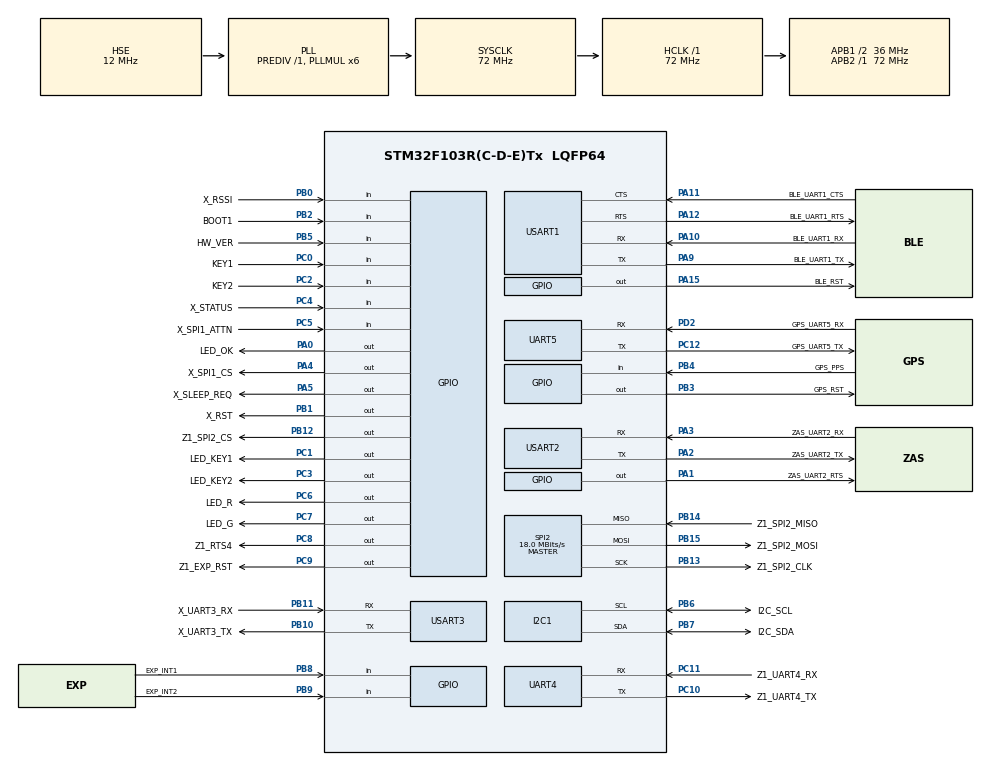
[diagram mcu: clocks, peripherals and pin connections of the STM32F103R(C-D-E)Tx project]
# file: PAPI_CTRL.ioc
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IWDG.Prescaler=IWDG_PRESCALER_16
Mcu.Family=STM32F1
Mcu.Name=STM32F103R(C-D-E)Tx
Mcu.Package=LQFP64
NVIC.PriorityGroup=NVIC_PRIORITYGROUP_4
PA0-WKUP.GPIO_Label=LED_OK
PA0-WKUP.Signal=GPIO_Output
PA1.GPIO_Label=ZAS_UART2_RTS
PA1.Signal=GPIO_Output
PA10.GPIO_Label=BLE_UART1_RX
PA10.Mode=Asynchronous
PA10.Signal=USART1_RX
PA11.GPIO_Label=BLE_UART1_CTS
PA11.Mode=CTS_RTS
PA11.Signal=USART1_CTS
PA12.GPIO_Label=BLE_UART1_RTS
PA12.Mode=CTS_RTS
PA12.Signal=USART1_RTS
PA13.Mode=Serial_Wire
PA13.Signal=SYS_JTMS-SWDIO
PA14.Mode=Serial_Wire
PA14.Signal=SYS_JTCK-SWCLK
PA15.GPIO_Label=BLE_RST
PA15.Signal=GPIO_Output
PA2.GPIO_Label=ZAS_UART2_TX
PA2.Mode=Asynchronous
PA2.Signal=USART2_TX
PA3.GPIO_Label=ZAS_UART2_RX
PA3.Mode=Asynchronous
PA3.Signal=USART2_RX
PA4.GPIO_Label=X_SPI1_CS
PA4.PinState=GPIO_PIN_SET
PA4.Signal=GPIO_Output
PA5.GPIO_Label=X_SLEEP_REQ
PA5.Signal=GPIO_Output
PA9.GPIO_Label=BLE_UART1_TX
PA9.Mode=Asynchronous
PA9.Signal=USART1_TX
PB0.GPIO_Label=X_RSSI
PB0.Signal=GPIO_Input
PB1.GPIO_Label=X_RST
PB1.Signal=GPIO_Output
PB10.GPIO_Label=X_UART3_TX
PB10.Mode=Asynchronous
PB10.Signal=USART3_TX
PB11.GPIO_Label=X_UART3_RX
PB11.Mode=Asynchronous
PB11.Signal=USART3_RX
PB12.GPIO_Label=Z1_SPI2_CS
PB12.Signal=GPIO_Output
PB13.GPIO_Label=Z1_SPI2_CLK
PB13.Mode=Full_Duplex_Master
PB13.Signal=SPI2_SCK
PB14.GPIO_Label=Z1_SPI2_MISO
PB14.Mode=Full_Duplex_Master
PB14.Signal=SPI2_MISO
PB15.GPIO_Label=Z1_SPI2_MOSI
PB15.Mode=Full_Duplex_Master
PB15.Signal=SPI2_MOSI
PB2.GPIO_Label=BOOT1
PB2.Signal=GPIO_Input
PB3.GPIO_Label=GPS_RST
PB3.Signal=GPIO_Output
PB4.GPIO_Label=GPS_PPS
PB4.Signal=GPIO_Input
PB5.GPIO_Label=HW_VER
PB5.Signal=GPIO_Input
PB6.GPIO_Label=I2C_SCL
PB6.Mode=I2C
PB6.Signal=I2C1_SCL
PB7.GPIO_Label=I2C_SDA
PB7.Mode=I2C
PB7.Signal=I2C1_SDA
PB8.GPIO_Label=EXP_INT1
PB8.GPIO_PuPd=GPIO_PULLUP
PB8.Signal=GPIO_Input
PB9.GPIO_Label=EXP_INT2
PB9.GPIO_PuPd=GPIO_PULLUP
PB9.Signal=GPIO_Input
PC0.GPIO_Label=KEY1
PC0.GPIO_PuPd=GPIO_PULLUP
PC0.Signal=GPIO_Input
PC1.GPIO_Label=LED_KEY1
PC1.Signal=GPIO_Output
PC10.GPIO_Label=Z1_UART4_TX
PC10.Mode=Asynchronous
PC10.Signal=UART4_TX
PC11.GPIO_Label=Z1_UART4_RX
PC11.Mode=Asynchronous
PC11.Signal=UART4_RX
PC12.GPIO_Label=GPS_UART5_TX
PC12.Mode=Asynchronous
PC12.Signal=UART5_TX
PC14-OSC32_IN.Mode=LSE-External-Oscillator
PC14-OSC32_IN.Signal=RCC_OSC32_IN
PC15-OSC32_OUT.Mode=LSE-External-Oscillator
PC15-OSC32_OUT.Signal=RCC_OSC32_OUT
PC2.GPIO_Label=KEY2
PC2.GPIO_PuPd=GPIO_PULLUP
PC2.Signal=GPIO_Input
PC3.GPIO_Label=LED_KEY2
PC3.Signal=GPIO_Output
PC4.GPIO_Label=X_STATUS
PC4.Signal=GPIO_Input
PC5.GPIO_Label=X_SPI1_ATTN
PC5.Signal=GPIO_Input
PC6.GPIO_Label=LED_R
PC6.Signal=GPIO_Output
PC7.GPIO_Label=LED_G
PC7.Signal=GPIO_Output
PC8.GPIO_Label=Z1_RTS4
PC8.Signal=GPIO_Output
PC9.GPIO_Label=Z1_EXP_RST
PC9.Signal=GPIO_Output
PD0-OSC_IN.Mode=HSE-External-Oscillator
PD0-OSC_IN.Signal=RCC_OSC_IN
PD1-OSC_OUT.Mode=HSE-External-Oscillator
PD1-OSC_OUT.Signal=RCC_OSC_OUT
PD2.GPIO_Label=GPS_UART5_RX
PD2.Mode=Asynchronous
PD2.Signal=UART5_RX
ProjectManager.HeapSize=0x200
ProjectManager.StackSize=0x400
ProjectManager.TargetToolchain=STM32CubeIDE
RCC.AHBFreq_Value=72000000
RCC.APB1CLKDivider=RCC_HCLK_DIV2
RCC.APB1Freq_Value=36000000
RCC.APB1TimFreq_Value=72000000
RCC.APB2Freq_Value=72000000
RCC.APB2TimFreq_Value=72000000
RCC.HCLKFreq_Value=72000000
RCC.HSE_VALUE=12000000
RCC.PLLMUL=RCC_PLL_MUL6
RCC.PLLSourceVirtual=RCC_PLLSOURCE_HSE
RCC.SYSCLKFreq_VALUE=72000000
RCC.SYSCLKSource=RCC_SYSCLKSOURCE_PLLCLK
RCC.USBFreq_Value=72000000
SPI2.BaudRatePrescaler=SPI_BAUDRATEPRESCALER_2
SPI2.CalculateBaudRate=18.0 MBits/s
SPI2.Direction=SPI_DIRECTION_2LINES
SPI2.Mode=SPI_MODE_MASTER
SPI2.VirtualType=VM_MASTER
UART4.VirtualMode=Asynchronous
UART5.VirtualMode=Asynchronous
USART1.VirtualMode=VM_ASYNC
USART2.VirtualMode=VM_ASYNC
USART3.VirtualMode=VM_ASYNC
VP_IWDG_VS_IWDG.Mode=IWDG_Activate
board=custom

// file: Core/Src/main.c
/* USER CODE BEGIN Header */
/**
  ******************************************************************************
  * @file           : main.c
  * @brief          : Main program body
  ******************************************************************************
  * @attention
  *
  * <h2><center>&copy; Copyright (c) 2022 STMicroelectronics.
  * All rights reserved.</center></h2>
  *
  * This software component is licensed by ST under BSD 3-Clause license,
  * the "License"; You may not use this file except in compliance with the
  * License. You may obtain a copy of the License at:
  *                        opensource.org/licenses/BSD-3-Clause
  *
  ******************************************************************************
  */
/* USER CODE END Header */
#include "main.h"

I2C_HandleTypeDef hi2c1;

IWDG_HandleTypeDef hiwdg;

SPI_HandleTypeDef hspi2;

UART_HandleTypeDef huart4;
UART_HandleTypeDef huart5;
UART_HandleTypeDef huart1;
UART_HandleTypeDef huart2;
UART_HandleTypeDef huart3;

void SystemClock_Config(void);
static void MX_GPIO_Init(void);
static void MX_I2C1_Init(void);
static void MX_SPI2_Init(void);
static void MX_UART4_Init(void);
static void MX_UART5_Init(void);
static void MX_USART1_UART_Init(void);
static void MX_USART2_UART_Init(void);
static void MX_USART3_UART_Init(void);
static void MX_IWDG_Init(void);

/* USER CODE BEGIN 0 */

extern void uMain(void);

void MxStart(void) {
	  MX_GPIO_Init();
	  MX_I2C1_Init();
//	  MX_SPI1_Init();
//	  MX_SPI2_Init();
//	  MX_UART4_Init();
//	  MX_UART5_Init();
//	  MX_USART1_UART_Init();
//	  MX_USART2_UART_Init();
//	  MX_USART3_UART_Init();
//	  MX_IWDG_Init();
}

/* USER CODE END 0 */

int main(void)
{

  /* MCU Configuration--------------------------------------------------------*/

  /* Reset of all peripherals, Initializes the Flash interface and the Systick. */
  HAL_Init();

  /* Configure the system clock */
  SystemClock_Config();

  /* USER CODE BEGIN SysInit */
	uMain();

  /* USER CODE END SysInit */

  /* Initialize all configured peripherals */
  MX_GPIO_Init();
  MX_I2C1_Init();
  MX_SPI2_Init();
  MX_UART4_Init();
  MX_UART5_Init();
  MX_USART1_UART_Init();
  MX_USART2_UART_Init();
  MX_USART3_UART_Init();
  MX_IWDG_Init();

  /* Infinite loop */
  while (1)
  {

  }
}

void SystemClock_Config(void)
{
  RCC_OscInitTypeDef RCC_OscInitStruct = {0};
  RCC_ClkInitTypeDef RCC_ClkInitStruct = {0};

  /** Initializes the RCC Oscillators according to the specified parameters
  * in the RCC_OscInitTypeDef structure.
  */
  RCC_OscInitStruct.OscillatorType = RCC_OSCILLATORTYPE_LSI|RCC_OSCILLATORTYPE_HSE;
  RCC_OscInitStruct.HSEState = RCC_HSE_ON;
  RCC_OscInitStruct.HSEPredivValue = RCC_HSE_PREDIV_DIV1;
  RCC_OscInitStruct.HSIState = RCC_HSI_ON;
  RCC_OscInitStruct.LSIState = RCC_LSI_ON;
  RCC_OscInitStruct.PLL.PLLState = RCC_PLL_ON;
  RCC_OscInitStruct.PLL.PLLSource = RCC_PLLSOURCE_HSE;
  RCC_OscInitStruct.PLL.PLLMUL = RCC_PLL_MUL6;
  if (HAL_RCC_OscConfig(&RCC_OscInitStruct) != HAL_OK)
  {
    Error_Handler();
  }
  /** Initializes the CPU, AHB and APB buses clocks
  */
  RCC_ClkInitStruct.ClockType = RCC_CLOCKTYPE_HCLK|RCC_CLOCKTYPE_SYSCLK
                              |RCC_CLOCKTYPE_PCLK1|RCC_CLOCKTYPE_PCLK2;
  RCC_ClkInitStruct.SYSCLKSource = RCC_SYSCLKSOURCE_PLLCLK;
  RCC_ClkInitStruct.AHBCLKDivider = RCC_SYSCLK_DIV1;
  RCC_ClkInitStruct.APB1CLKDivider = RCC_HCLK_DIV2;
  RCC_ClkInitStruct.APB2CLKDivider = RCC_HCLK_DIV1;

  if (HAL_RCC_ClockConfig(&RCC_ClkInitStruct, FLASH_LATENCY_2) != HAL_OK)
  {
    Error_Handler();
  }
}

static void MX_I2C1_Init(void)
{

  hi2c1.Instance = I2C1;
  hi2c1.Init.ClockSpeed = 100000;
  hi2c1.Init.DutyCycle = I2C_DUTYCYCLE_2;
  hi2c1.Init.OwnAddress1 = 0;
  hi2c1.Init.AddressingMode = I2C_ADDRESSINGMODE_7BIT;
  hi2c1.Init.DualAddressMode = I2C_DUALADDRESS_DISABLE;
  hi2c1.Init.OwnAddress2 = 0;
  hi2c1.Init.GeneralCallMode = I2C_GENERALCALL_DISABLE;
  hi2c1.Init.NoStretchMode = I2C_NOSTRETCH_DISABLE;
  if (HAL_I2C_Init(&hi2c1) != HAL_OK)
  {
    Error_Handler();
  }

}

static void MX_IWDG_Init(void)
{

  hiwdg.Instance = IWDG;
  hiwdg.Init.Prescaler = IWDG_PRESCALER_16;
  hiwdg.Init.Reload = 4095;
  if (HAL_IWDG_Init(&hiwdg) != HAL_OK)
  {
    Error_Handler();
  }

}

static void MX_SPI2_Init(void)
{

  /* SPI2 parameter configuration*/
  hspi2.Instance = SPI2;
  hspi2.Init.Mode = SPI_MODE_MASTER;
  hspi2.Init.Direction = SPI_DIRECTION_2LINES;
  hspi2.Init.DataSize = SPI_DATASIZE_8BIT;
  hspi2.Init.CLKPolarity = SPI_POLARITY_LOW;
  hspi2.Init.CLKPhase = SPI_PHASE_1EDGE;
  hspi2.Init.NSS = SPI_NSS_SOFT;
  hspi2.Init.BaudRatePrescaler = SPI_BAUDRATEPRESCALER_2;
  hspi2.Init.FirstBit = SPI_FIRSTBIT_MSB;
  hspi2.Init.TIMode = SPI_TIMODE_DISABLE;
  hspi2.Init.CRCCalculation = SPI_CRCCALCULATION_DISABLE;
  hspi2.Init.CRCPolynomial = 10;
  if (HAL_SPI_Init(&hspi2) != HAL_OK)
  {
    Error_Handler();
  }

}

static void MX_UART4_Init(void)
{

  huart4.Instance = UART4;
  huart4.Init.BaudRate = 115200;
  huart4.Init.WordLength = UART_WORDLENGTH_8B;
  huart4.Init.StopBits = UART_STOPBITS_1;
  huart4.Init.Parity = UART_PARITY_NONE;
  huart4.Init.Mode = UART_MODE_TX_RX;
  huart4.Init.HwFlowCtl = UART_HWCONTROL_NONE;
  huart4.Init.OverSampling = UART_OVERSAMPLING_16;
  if (HAL_UART_Init(&huart4) != HAL_OK)
  {
    Error_Handler();
  }

}

static void MX_UART5_Init(void)
{

  huart5.Instance = UART5;
  huart5.Init.BaudRate = 115200;
  huart5.Init.WordLength = UART_WORDLENGTH_8B;
  huart5.Init.StopBits = UART_STOPBITS_1;
  huart5.Init.Parity = UART_PARITY_NONE;
  huart5.Init.Mode = UART_MODE_TX_RX;
  huart5.Init.HwFlowCtl = UART_HWCONTROL_NONE;
  huart5.Init.OverSampling = UART_OVERSAMPLING_16;
  if (HAL_UART_Init(&huart5) != HAL_OK)
  {
    Error_Handler();
  }

}

static void MX_USART1_UART_Init(void)
{

  huart1.Instance = USART1;
  huart1.Init.BaudRate = 115200;
  huart1.Init.WordLength = UART_WORDLENGTH_8B;
  huart1.Init.StopBits = UART_STOPBITS_1;
  huart1.Init.Parity = UART_PARITY_NONE;
  huart1.Init.Mode = UART_MODE_TX_RX;
  huart1.Init.HwFlowCtl = UART_HWCONTROL_RTS_CTS;
  huart1.Init.OverSampling = UART_OVERSAMPLING_16;
  if (HAL_UART_Init(&huart1) != HAL_OK)
  {
    Error_Handler();
  }

}

static void MX_USART2_UART_Init(void)
{

  huart2.Instance = USART2;
  huart2.Init.BaudRate = 115200;
  huart2.Init.WordLength = UART_WORDLENGTH_8B;
  huart2.Init.StopBits = UART_STOPBITS_1;
  huart2.Init.Parity = UART_PARITY_NONE;
  huart2.Init.Mode = UART_MODE_TX_RX;
  huart2.Init.HwFlowCtl = UART_HWCONTROL_NONE;
  huart2.Init.OverSampling = UART_OVERSAMPLING_16;
  if (HAL_UART_Init(&huart2) != HAL_OK)
  {
    Error_Handler();
  }

}

static void MX_USART3_UART_Init(void)
{

  huart3.Instance = USART3;
  huart3.Init.BaudRate = 115200;
  huart3.Init.WordLength = UART_WORDLENGTH_8B;
  huart3.Init.StopBits = UART_STOPBITS_1;
  huart3.Init.Parity = UART_PARITY_NONE;
  huart3.Init.Mode = UART_MODE_TX_RX;
  huart3.Init.HwFlowCtl = UART_HWCONTROL_NONE;
  huart3.Init.OverSampling = UART_OVERSAMPLING_16;
  if (HAL_UART_Init(&huart3) != HAL_OK)
  {
    Error_Handler();
  }

}

static void MX_GPIO_Init(void)
{
  GPIO_InitTypeDef GPIO_InitStruct = {0};

  /* GPIO Ports Clock Enable */
  __HAL_RCC_GPIOC_CLK_ENABLE();
  __HAL_RCC_GPIOD_CLK_ENABLE();
  __HAL_RCC_GPIOA_CLK_ENABLE();
  __HAL_RCC_GPIOB_CLK_ENABLE();

  /*Configure GPIO pin Output Level */
  HAL_GPIO_WritePin(GPIOC, LED_KEY1_Pin|LED_KEY2_Pin|LED_R_Pin|LED_G_Pin
                          |Z1_RTS4_Pin|Z1_EXP_RST_Pin, GPIO_PIN_RESET);

  /*Configure GPIO pin Output Level */
  HAL_GPIO_WritePin(GPIOA, LED_OK_Pin|ZAS_UART2_RTS_Pin|X_SLEEP_REQ_Pin|BLE_RST_Pin, GPIO_PIN_RESET);

  /*Configure GPIO pin Output Level */
  HAL_GPIO_WritePin(X_SPI1_CS_GPIO_Port, X_SPI1_CS_Pin, GPIO_PIN_SET);

  /*Configure GPIO pin Output Level */
  HAL_GPIO_WritePin(GPIOB, X_RST_Pin|Z1_SPI2_CS_Pin|GPS_RST_Pin, GPIO_PIN_RESET);

  /*Configure GPIO pins : KEY1_Pin KEY2_Pin */
  GPIO_InitStruct.Pin = KEY1_Pin|KEY2_Pin;
  GPIO_InitStruct.Mode = GPIO_MODE_INPUT;
  GPIO_InitStruct.Pull = GPIO_PULLUP;
  HAL_GPIO_Init(GPIOC, &GPIO_InitStruct);

  /*Configure GPIO pins : LED_KEY1_Pin LED_KEY2_Pin LED_R_Pin LED_G_Pin
                           Z1_RTS4_Pin Z1_EXP_RST_Pin */
  GPIO_InitStruct.Pin = LED_KEY1_Pin|LED_KEY2_Pin|LED_R_Pin|LED_G_Pin
                          |Z1_RTS4_Pin|Z1_EXP_RST_Pin;
  GPIO_InitStruct.Mode = GPIO_MODE_OUTPUT_PP;
  GPIO_InitStruct.Pull = GPIO_NOPULL;
  GPIO_InitStruct.Speed = GPIO_SPEED_FREQ_LOW;
  HAL_GPIO_Init(GPIOC, &GPIO_InitStruct);

  /*Configure GPIO pins : LED_OK_Pin ZAS_UART2_RTS_Pin X_SPI1_CS_Pin X_SLEEP_REQ_Pin
                           BLE_RST_Pin */
  GPIO_InitStruct.Pin = LED_OK_Pin|ZAS_UART2_RTS_Pin|X_SPI1_CS_Pin|X_SLEEP_REQ_Pin
                          |BLE_RST_Pin;
  GPIO_InitStruct.Mode = GPIO_MODE_OUTPUT_PP;
  GPIO_InitStruct.Pull = GPIO_NOPULL;
  GPIO_InitStruct.Speed = GPIO_SPEED_FREQ_LOW;
  HAL_GPIO_Init(GPIOA, &GPIO_InitStruct);

  /*Configure GPIO pins : X_STATUS_Pin X_SPI1_ATTN_Pin */
  GPIO_InitStruct.Pin = X_STATUS_Pin|X_SPI1_ATTN_Pin;
  GPIO_InitStruct.Mode = GPIO_MODE_INPUT;
  GPIO_InitStruct.Pull = GPIO_NOPULL;
  HAL_GPIO_Init(GPIOC, &GPIO_InitStruct);

  /*Configure GPIO pins : X_RSSI_Pin BOOT1_Pin GPS_PPS_Pin HW_VER_Pin */
  GPIO_InitStruct.Pin = X_RSSI_Pin|BOOT1_Pin|GPS_PPS_Pin|HW_VER_Pin;
  GPIO_InitStruct.Mode = GPIO_MODE_INPUT;
  GPIO_InitStruct.Pull = GPIO_NOPULL;
  HAL_GPIO_Init(GPIOB, &GPIO_InitStruct);

  /*Configure GPIO pins : X_RST_Pin Z1_SPI2_CS_Pin GPS_RST_Pin */
  GPIO_InitStruct.Pin = X_RST_Pin|Z1_SPI2_CS_Pin|GPS_RST_Pin;
  GPIO_InitStruct.Mode = GPIO_MODE_OUTPUT_PP;
  GPIO_InitStruct.Pull = GPIO_NOPULL;
  GPIO_InitStruct.Speed = GPIO_SPEED_FREQ_LOW;
  HAL_GPIO_Init(GPIOB, &GPIO_InitStruct);

  /*Configure GPIO pins : EXP_INT1_Pin EXP_INT2_Pin */
  GPIO_InitStruct.Pin = EXP_INT1_Pin|EXP_INT2_Pin;
  GPIO_InitStruct.Mode = GPIO_MODE_INPUT;
  GPIO_InitStruct.Pull = GPIO_PULLUP;
  HAL_GPIO_Init(GPIOB, &GPIO_InitStruct);

}

void Error_Handler(void)
{
  __disable_irq();
  while (1)
  {
  }
}

/************************ (C) COPYRIGHT STMicroelectronics *****END OF FILE****/
